# STM32H7B3ZIT6Q register map
File version: 1.0
Registers are 32-bit, access not given, reset 0x0 unless marked. A register's access mark holds for its fields unless they carry their own. Offsets are from the block's base; [hi:lo] are bit positions; {n}, {i} and the like mark numbered series.

## GFXMMU
Base 0x5200C000
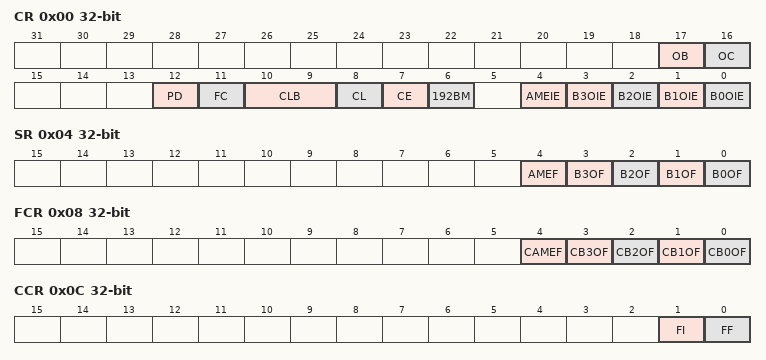
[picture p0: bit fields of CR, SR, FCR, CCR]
0x00 CR
  [17] OB, [16] OC, [12] PD, [11] FC, [10:9] CLB, [8] CL, [7] CE, [6] 192BM, [4] AMEIE, [n] B{n}OIE (n=0..3)
0x04 SR
  [4] AMEF, [n] B{n}OF (n=0..3)
0x08 FCR
  [4] CAMEF, [n] CB{n}OF (n=0..3)
0x0C CCR
  [1] FI, [0] FF
0x10 DVR
  [31:0] DV
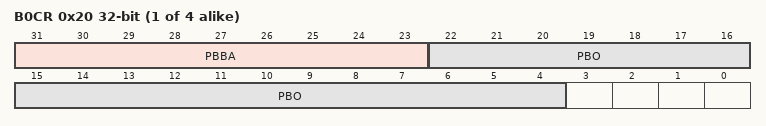
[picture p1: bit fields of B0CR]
{0x20+4i} B{i}CR (i=0..3)
  [31:23] PBBA, [22:4] PBO
0x1000 LUT.0
0x1004 LUT.1
0x1008 LUT.2
0x100C LUT.3
0x1010 LUT.4
0x1014 LUT.5
0x1018 LUT.6
0x101C LUT.7
0x1020 LUT.8
0x1024 LUT.9
0x1028 LUT.10
0x102C LUT.11
0x1030 LUT.12
0x1034 LUT.13
0x1038 LUT.14
0x103C LUT.15
0x1040 LUT.16
0x1044 LUT.17
0x1048 LUT.18
0x104C LUT.19
0x1050 LUT.20
0x1054 LUT.21
0x1058 LUT.22
0x105C LUT.23
0x1060 LUT.24
0x1064 LUT.25
0x1068 LUT.26
0x106C LUT.27
0x1070 LUT.28
0x1074 LUT.29
0x1078 LUT.30
0x107C LUT.31
0x1080 LUT.32
0x1084 LUT.33
0x1088 LUT.34
0x108C LUT.35
0x1090 LUT.36
0x1094 LUT.37
0x1098 LUT.38
0x109C LUT.39
0x10A0 LUT.40
0x10A4 LUT.41
0x10A8 LUT.42
0x10AC LUT.43
0x10B0 LUT.44
0x10B4 LUT.45
0x10B8 LUT.46
0x10BC LUT.47
0x10C0 LUT.48
0x10C4 LUT.49
0x10C8 LUT.50
0x10CC LUT.51
0x10D0 LUT.52
0x10D4 LUT.53
0x10D8 LUT.54
0x10DC LUT.55
0x10E0 LUT.56
0x10E4 LUT.57
0x10E8 LUT.58
0x10EC LUT.59
0x10F0 LUT.60
0x10F4 LUT.61
0x10F8 LUT.62
0x10FC LUT.63
0x1100 LUT.64
0x1104 LUT.65
0x1108 LUT.66
0x110C LUT.67
0x1110 LUT.68
0x1114 LUT.69
0x1118 LUT.70
0x111C LUT.71
0x1120 LUT.72
0x1124 LUT.73
0x1128 LUT.74
0x112C LUT.75
0x1130 LUT.76
0x1134 LUT.77
0x1138 LUT.78
0x113C LUT.79
0x1140 LUT.80
0x1144 LUT.81
0x1148 LUT.82
0x114C LUT.83
0x1150 LUT.84
0x1154 LUT.85
0x1158 LUT.86
0x115C LUT.87
0x1160 LUT.88
0x1164 LUT.89
0x1168 LUT.90
0x116C LUT.91
0x1170 LUT.92
0x1174 LUT.93
0x1178 LUT.94
0x117C LUT.95
0x1180 LUT.96
0x1184 LUT.97
0x1188 LUT.98
0x118C LUT.99
0x1190 LUT.100
0x1194 LUT.101
0x1198 LUT.102
0x119C LUT.103
0x11A0 LUT.104
0x11A4 LUT.105
0x11A8 LUT.106
0x11AC LUT.107
0x11B0 LUT.108
0x11B4 LUT.109
0x11B8 LUT.110
0x11BC LUT.111
0x11C0 LUT.112
0x11C4 LUT.113
0x11C8 LUT.114
0x11CC LUT.115
0x11D0 LUT.116
0x11D4 LUT.117
0x11D8 LUT.118
0x11DC LUT.119
0x11E0 LUT.120
0x11E4 LUT.121
0x11E8 LUT.122
0x11EC LUT.123
0x11F0 LUT.124
0x11F4 LUT.125
0x11F8 LUT.126
0x11FC LUT.127
0x1200 LUT.128
0x1204 LUT.129
0x1208 LUT.130
0x120C LUT.131
0x1210 LUT.132
0x1214 LUT.133
0x1218 LUT.134
0x121C LUT.135
0x1220 LUT.136
0x1224 LUT.137
0x1228 LUT.138
0x122C LUT.139
0x1230 LUT.140
0x1234 LUT.141
0x1238 LUT.142
0x123C LUT.143
0x1240 LUT.144
0x1244 LUT.145
0x1248 LUT.146
0x124C LUT.147
0x1250 LUT.148
0x1254 LUT.149
0x1258 LUT.150
0x125C LUT.151
0x1260 LUT.152
0x1264 LUT.153
0x1268 LUT.154
0x126C LUT.155
0x1270 LUT.156
0x1274 LUT.157
0x1278 LUT.158
0x127C LUT.159
0x1280 LUT.160
0x1284 LUT.161
0x1288 LUT.162
0x128C LUT.163
0x1290 LUT.164
0x1294 LUT.165
0x1298 LUT.166
0x129C LUT.167
0x12A0 LUT.168
0x12A4 LUT.169
0x12A8 LUT.170
0x12AC LUT.171
0x12B0 LUT.172
0x12B4 LUT.173
0x12B8 LUT.174
0x12BC LUT.175
0x12C0 LUT.176
0x12C4 LUT.177
0x12C8 LUT.178
0x12CC LUT.179
0x12D0 LUT.180
0x12D4 LUT.181
0x12D8 LUT.182
0x12DC LUT.183
0x12E0 LUT.184
0x12E4 LUT.185
0x12E8 LUT.186
0x12EC LUT.187
0x12F0 LUT.188
0x12F4 LUT.189
0x12F8 LUT.190
0x12FC LUT.191
0x1300 LUT.192
0x1304 LUT.193
0x1308 LUT.194
0x130C LUT.195
0x1310 LUT.196
0x1314 LUT.197
0x1318 LUT.198
0x131C LUT.199
0x1320 LUT.200
0x1324 LUT.201
0x1328 LUT.202
0x132C LUT.203
0x1330 LUT.204
0x1334 LUT.205
0x1338 LUT.206
0x133C LUT.207
0x1340 LUT.208
0x1344 LUT.209
0x1348 LUT.210
0x134C LUT.211
0x1350 LUT.212
0x1354 LUT.213
0x1358 LUT.214
0x135C LUT.215
0x1360 LUT.216
0x1364 LUT.217
0x1368 LUT.218
0x136C LUT.219
0x1370 LUT.220
0x1374 LUT.221
0x1378 LUT.222
0x137C LUT.223
0x1380 LUT.224
0x1384 LUT.225
0x1388 LUT.226
0x138C LUT.227
0x1390 LUT.228
0x1394 LUT.229
0x1398 LUT.230
0x139C LUT.231
0x13A0 LUT.232
0x13A4 LUT.233
0x13A8 LUT.234
0x13AC LUT.235
0x13B0 LUT.236
0x13B4 LUT.237
0x13B8 LUT.238
0x13BC LUT.239
0x13C0 LUT.240
0x13C4 LUT.241
0x13C8 LUT.242
0x13CC LUT.243
0x13D0 LUT.244
0x13D4 LUT.245
0x13D8 LUT.246
0x13DC LUT.247
0x13E0 LUT.248
0x13E4 LUT.249
0x13E8 LUT.250
0x13EC LUT.251
0x13F0 LUT.252
0x13F4 LUT.253
0x13F8 LUT.254
0x13FC LUT.255
0x1400 LUT.256
0x1404 LUT.257
0x1408 LUT.258
0x140C LUT.259
0x1410 LUT.260
0x1414 LUT.261
0x1418 LUT.262
0x141C LUT.263
0x1420 LUT.264
0x1424 LUT.265
0x1428 LUT.266
0x142C LUT.267
0x1430 LUT.268
0x1434 LUT.269
0x1438 LUT.270
0x143C LUT.271
0x1440 LUT.272
0x1444 LUT.273
0x1448 LUT.274
0x144C LUT.275
0x1450 LUT.276
0x1454 LUT.277
0x1458 LUT.278
0x145C LUT.279
0x1460 LUT.280
0x1464 LUT.281
0x1468 LUT.282
0x146C LUT.283
0x1470 LUT.284
0x1474 LUT.285
0x1478 LUT.286
0x147C LUT.287
0x1480 LUT.288
0x1484 LUT.289
0x1488 LUT.290
0x148C LUT.291
0x1490 LUT.292
0x1494 LUT.293
0x1498 LUT.294
0x149C LUT.295
0x14A0 LUT.296
0x14A4 LUT.297
0x14A8 LUT.298
0x14AC LUT.299
0x14B0 LUT.300
0x14B4 LUT.301
0x14B8 LUT.302
0x14BC LUT.303
0x14C0 LUT.304
0x14C4 LUT.305
0x14C8 LUT.306
0x14CC LUT.307
0x14D0 LUT.308
0x14D4 LUT.309
0x14D8 LUT.310
0x14DC LUT.311
0x14E0 LUT.312
0x14E4 LUT.313
0x14E8 LUT.314
0x14EC LUT.315
0x14F0 LUT.316
0x14F4 LUT.317
0x14F8 LUT.318
0x14FC LUT.319
0x1500 LUT.320
0x1504 LUT.321
0x1508 LUT.322
0x150C LUT.323
0x1510 LUT.324
0x1514 LUT.325
0x1518 LUT.326
0x151C LUT.327
0x1520 LUT.328
0x1524 LUT.329
0x1528 LUT.330
0x152C LUT.331
0x1530 LUT.332
0x1534 LUT.333
0x1538 LUT.334
0x153C LUT.335
0x1540 LUT.336
0x1544 LUT.337
0x1548 LUT.338
0x154C LUT.339
0x1550 LUT.340
0x1554 LUT.341
0x1558 LUT.342
0x155C LUT.343
0x1560 LUT.344
0x1564 LUT.345
0x1568 LUT.346
0x156C LUT.347
0x1570 LUT.348
0x1574 LUT.349
0x1578 LUT.350
0x157C LUT.351
0x1580 LUT.352
0x1584 LUT.353
0x1588 LUT.354
0x158C LUT.355
0x1590 LUT.356
0x1594 LUT.357
0x1598 LUT.358
0x159C LUT.359
0x15A0 LUT.360
0x15A4 LUT.361
0x15A8 LUT.362
0x15AC LUT.363
0x15B0 LUT.364
0x15B4 LUT.365
0x15B8 LUT.366
0x15BC LUT.367
0x15C0 LUT.368
0x15C4 LUT.369
0x15C8 LUT.370
0x15CC LUT.371
0x15D0 LUT.372
0x15D4 LUT.373
0x15D8 LUT.374
0x15DC LUT.375
0x15E0 LUT.376
0x15E4 LUT.377
0x15E8 LUT.378
0x15EC LUT.379
0x15F0 LUT.380
0x15F4 LUT.381
0x15F8 LUT.382
0x15FC LUT.383
0x1600 LUT.384
0x1604 LUT.385
0x1608 LUT.386
0x160C LUT.387
0x1610 LUT.388
0x1614 LUT.389
0x1618 LUT.390
0x161C LUT.391
0x1620 LUT.392
0x1624 LUT.393
0x1628 LUT.394
0x162C LUT.395
0x1630 LUT.396
0x1634 LUT.397
0x1638 LUT.398
0x163C LUT.399
0x1640 LUT.400
0x1644 LUT.401
0x1648 LUT.402
0x164C LUT.403
0x1650 LUT.404
0x1654 LUT.405
0x1658 LUT.406
0x165C LUT.407
0x1660 LUT.408
0x1664 LUT.409
0x1668 LUT.410
0x166C LUT.411
0x1670 LUT.412
0x1674 LUT.413
0x1678 LUT.414
0x167C LUT.415
0x1680 LUT.416
0x1684 LUT.417
0x1688 LUT.418
0x168C LUT.419
0x1690 LUT.420
0x1694 LUT.421
0x1698 LUT.422
0x169C LUT.423
0x16A0 LUT.424
0x16A4 LUT.425
0x16A8 LUT.426
0x16AC LUT.427
0x16B0 LUT.428
0x16B4 LUT.429
0x16B8 LUT.430
0x16BC LUT.431
0x16C0 LUT.432
0x16C4 LUT.433
0x16C8 LUT.434
0x16CC LUT.435
0x16D0 LUT.436
0x16D4 LUT.437
0x16D8 LUT.438
0x16DC LUT.439
0x16E0 LUT.440
0x16E4 LUT.441
0x16E8 LUT.442
0x16EC LUT.443
0x16F0 LUT.444
0x16F4 LUT.445
0x16F8 LUT.446
0x16FC LUT.447
0x1700 LUT.448
0x1704 LUT.449
0x1708 LUT.450
0x170C LUT.451
0x1710 LUT.452
0x1714 LUT.453
0x1718 LUT.454
0x171C LUT.455
0x1720 LUT.456
0x1724 LUT.457
0x1728 LUT.458
0x172C LUT.459
0x1730 LUT.460
0x1734 LUT.461
0x1738 LUT.462
0x173C LUT.463
0x1740 LUT.464
0x1744 LUT.465
0x1748 LUT.466
0x174C LUT.467
0x1750 LUT.468
0x1754 LUT.469
0x1758 LUT.470
0x175C LUT.471
0x1760 LUT.472
0x1764 LUT.473
0x1768 LUT.474
0x176C LUT.475
0x1770 LUT.476
0x1774 LUT.477
0x1778 LUT.478
0x177C LUT.479
0x1780 LUT.480
0x1784 LUT.481
0x1788 LUT.482
0x178C LUT.483
0x1790 LUT.484
0x1794 LUT.485
0x1798 LUT.486
0x179C LUT.487
0x17A0 LUT.488
0x17A4 LUT.489
0x17A8 LUT.490
0x17AC LUT.491
0x17B0 LUT.492
0x17B4 LUT.493
0x17B8 LUT.494
0x17BC LUT.495
0x17C0 LUT.496
0x17C4 LUT.497
0x17C8 LUT.498
0x17CC LUT.499
0x17D0 LUT.500
0x17D4 LUT.501
0x17D8 LUT.502
0x17DC LUT.503
0x17E0 LUT.504
0x17E4 LUT.505
0x17E8 LUT.506
0x17EC LUT.507
0x17F0 LUT.508
0x17F4 LUT.509
0x17F8 LUT.510
0x17FC LUT.511
0x1800 LUT.512
0x1804 LUT.513
0x1808 LUT.514
0x180C LUT.515
0x1810 LUT.516
0x1814 LUT.517
0x1818 LUT.518
0x181C LUT.519
0x1820 LUT.520
0x1824 LUT.521
0x1828 LUT.522
0x182C LUT.523
0x1830 LUT.524
0x1834 LUT.525
0x1838 LUT.526
0x183C LUT.527
0x1840 LUT.528
0x1844 LUT.529
0x1848 LUT.530
0x184C LUT.531
0x1850 LUT.532
0x1854 LUT.533
0x1858 LUT.534
0x185C LUT.535
0x1860 LUT.536
0x1864 LUT.537
0x1868 LUT.538
0x186C LUT.539
0x1870 LUT.540
0x1874 LUT.541
0x1878 LUT.542
0x187C LUT.543
0x1880 LUT.544
0x1884 LUT.545
0x1888 LUT.546
0x188C LUT.547
0x1890 LUT.548
0x1894 LUT.549
0x1898 LUT.550
0x189C LUT.551
0x18A0 LUT.552
0x18A4 LUT.553
0x18A8 LUT.554
0x18AC LUT.555
0x18B0 LUT.556
0x18B4 LUT.557
0x18B8 LUT.558
0x18BC LUT.559
0x18C0 LUT.560
0x18C4 LUT.561
0x18C8 LUT.562
0x18CC LUT.563
0x18D0 LUT.564
0x18D4 LUT.565
0x18D8 LUT.566
0x18DC LUT.567
0x18E0 LUT.568
0x18E4 LUT.569
0x18E8 LUT.570
0x18EC LUT.571
0x18F0 LUT.572
0x18F4 LUT.573
0x18F8 LUT.574
0x18FC LUT.575
0x1900 LUT.576
0x1904 LUT.577
0x1908 LUT.578
0x190C LUT.579
0x1910 LUT.580
0x1914 LUT.581
0x1918 LUT.582
0x191C LUT.583
0x1920 LUT.584
0x1924 LUT.585
0x1928 LUT.586
0x192C LUT.587
0x1930 LUT.588
0x1934 LUT.589
0x1938 LUT.590
0x193C LUT.591
0x1940 LUT.592
0x1944 LUT.593
0x1948 LUT.594
0x194C LUT.595
0x1950 LUT.596
0x1954 LUT.597
0x1958 LUT.598
0x195C LUT.599
0x1960 LUT.600
0x1964 LUT.601
0x1968 LUT.602
0x196C LUT.603
0x1970 LUT.604
0x1974 LUT.605
0x1978 LUT.606
0x197C LUT.607
0x1980 LUT.608
0x1984 LUT.609
0x1988 LUT.610
0x198C LUT.611
0x1990 LUT.612
0x1994 LUT.613
0x1998 LUT.614
0x199C LUT.615
0x19A0 LUT.616
0x19A4 LUT.617
0x19A8 LUT.618
0x19AC LUT.619
0x19B0 LUT.620
0x19B4 LUT.621
0x19B8 LUT.622
0x19BC LUT.623
0x19C0 LUT.624
0x19C4 LUT.625
0x19C8 LUT.626
0x19CC LUT.627
0x19D0 LUT.628
0x19D4 LUT.629
0x19D8 LUT.630
0x19DC LUT.631
0x19E0 LUT.632
0x19E4 LUT.633
0x19E8 LUT.634
0x19EC LUT.635
0x19F0 LUT.636
0x19F4 LUT.637
0x19F8 LUT.638
0x19FC LUT.639
0x1A00 LUT.640
0x1A04 LUT.641
0x1A08 LUT.642
0x1A0C LUT.643
0x1A10 LUT.644
0x1A14 LUT.645
0x1A18 LUT.646
0x1A1C LUT.647
0x1A20 LUT.648
0x1A24 LUT.649
0x1A28 LUT.650
0x1A2C LUT.651
0x1A30 LUT.652
0x1A34 LUT.653
0x1A38 LUT.654
0x1A3C LUT.655
0x1A40 LUT.656
0x1A44 LUT.657
0x1A48 LUT.658
0x1A4C LUT.659
0x1A50 LUT.660
0x1A54 LUT.661
0x1A58 LUT.662
0x1A5C LUT.663
0x1A60 LUT.664
0x1A64 LUT.665
0x1A68 LUT.666
0x1A6C LUT.667
0x1A70 LUT.668
0x1A74 LUT.669
0x1A78 LUT.670
0x1A7C LUT.671
0x1A80 LUT.672
0x1A84 LUT.673
0x1A88 LUT.674
0x1A8C LUT.675
0x1A90 LUT.676
0x1A94 LUT.677
0x1A98 LUT.678
0x1A9C LUT.679
0x1AA0 LUT.680
0x1AA4 LUT.681
0x1AA8 LUT.682
0x1AAC LUT.683
0x1AB0 LUT.684
0x1AB4 LUT.685
0x1AB8 LUT.686
0x1ABC LUT.687
0x1AC0 LUT.688
0x1AC4 LUT.689
0x1AC8 LUT.690
0x1ACC LUT.691
0x1AD0 LUT.692
0x1AD4 LUT.693
0x1AD8 LUT.694
0x1ADC LUT.695
0x1AE0 LUT.696
0x1AE4 LUT.697
0x1AE8 LUT.698
0x1AEC LUT.699
0x1AF0 LUT.700
0x1AF4 LUT.701
0x1AF8 LUT.702
0x1AFC LUT.703
0x1B00 LUT.704
0x1B04 LUT.705
0x1B08 LUT.706
0x1B0C LUT.707
0x1B10 LUT.708
0x1B14 LUT.709
0x1B18 LUT.710
0x1B1C LUT.711
0x1B20 LUT.712
0x1B24 LUT.713
0x1B28 LUT.714
0x1B2C LUT.715
0x1B30 LUT.716
0x1B34 LUT.717
0x1B38 LUT.718
0x1B3C LUT.719
0x1B40 LUT.720
0x1B44 LUT.721
0x1B48 LUT.722
0x1B4C LUT.723
0x1B50 LUT.724
0x1B54 LUT.725
0x1B58 LUT.726
0x1B5C LUT.727
0x1B60 LUT.728
0x1B64 LUT.729
0x1B68 LUT.730
0x1B6C LUT.731
0x1B70 LUT.732
0x1B74 LUT.733
0x1B78 LUT.734
0x1B7C LUT.735
0x1B80 LUT.736
0x1B84 LUT.737
0x1B88 LUT.738
0x1B8C LUT.739
0x1B90 LUT.740
0x1B94 LUT.741
0x1B98 LUT.742
0x1B9C LUT.743
0x1BA0 LUT.744
0x1BA4 LUT.745
0x1BA8 LUT.746
0x1BAC LUT.747
0x1BB0 LUT.748
0x1BB4 LUT.749
0x1BB8 LUT.750
0x1BBC LUT.751
0x1BC0 LUT.752
0x1BC4 LUT.753
0x1BC8 LUT.754
0x1BCC LUT.755
0x1BD0 LUT.756
0x1BD4 LUT.757
0x1BD8 LUT.758
0x1BDC LUT.759
0x1BE0 LUT.760
0x1BE4 LUT.761
0x1BE8 LUT.762
0x1BEC LUT.763
0x1BF0 LUT.764
0x1BF4 LUT.765
0x1BF8 LUT.766
0x1BFC LUT.767
0x1C00 LUT.768
0x1C04 LUT.769
0x1C08 LUT.770
0x1C0C LUT.771
0x1C10 LUT.772
0x1C14 LUT.773
0x1C18 LUT.774
0x1C1C LUT.775
0x1C20 LUT.776
0x1C24 LUT.777
0x1C28 LUT.778
0x1C2C LUT.779
0x1C30 LUT.780
0x1C34 LUT.781
0x1C38 LUT.782
0x1C3C LUT.783
0x1C40 LUT.784
0x1C44 LUT.785
0x1C48 LUT.786
0x1C4C LUT.787
0x1C50 LUT.788
0x1C54 LUT.789
0x1C58 LUT.790
0x1C5C LUT.791
0x1C60 LUT.792
0x1C64 LUT.793
0x1C68 LUT.794
0x1C6C LUT.795
0x1C70 LUT.796
0x1C74 LUT.797
0x1C78 LUT.798
0x1C7C LUT.799
0x1C80 LUT.800
0x1C84 LUT.801
0x1C88 LUT.802
0x1C8C LUT.803
0x1C90 LUT.804
0x1C94 LUT.805
0x1C98 LUT.806
0x1C9C LUT.807
0x1CA0 LUT.808
0x1CA4 LUT.809
0x1CA8 LUT.810
0x1CAC LUT.811
0x1CB0 LUT.812
0x1CB4 LUT.813
0x1CB8 LUT.814
0x1CBC LUT.815
0x1CC0 LUT.816
0x1CC4 LUT.817
0x1CC8 LUT.818
0x1CCC LUT.819
0x1CD0 LUT.820
0x1CD4 LUT.821
0x1CD8 LUT.822
0x1CDC LUT.823
0x1CE0 LUT.824
0x1CE4 LUT.825
0x1CE8 LUT.826
0x1CEC LUT.827
0x1CF0 LUT.828
0x1CF4 LUT.829
0x1CF8 LUT.830
0x1CFC LUT.831
0x1D00 LUT.832
0x1D04 LUT.833
0x1D08 LUT.834
0x1D0C LUT.835
0x1D10 LUT.836
0x1D14 LUT.837
0x1D18 LUT.838
0x1D1C LUT.839
0x1D20 LUT.840
0x1D24 LUT.841
0x1D28 LUT.842
0x1D2C LUT.843
0x1D30 LUT.844
0x1D34 LUT.845
0x1D38 LUT.846
0x1D3C LUT.847
0x1D40 LUT.848
0x1D44 LUT.849
0x1D48 LUT.850
0x1D4C LUT.851
0x1D50 LUT.852
0x1D54 LUT.853
0x1D58 LUT.854
0x1D5C LUT.855
0x1D60 LUT.856
0x1D64 LUT.857
0x1D68 LUT.858
0x1D6C LUT.859
0x1D70 LUT.860
0x1D74 LUT.861
0x1D78 LUT.862
0x1D7C LUT.863
0x1D80 LUT.864
0x1D84 LUT.865
0x1D88 LUT.866
0x1D8C LUT.867
0x1D90 LUT.868
0x1D94 LUT.869
0x1D98 LUT.870
0x1D9C LUT.871
0x1DA0 LUT.872
0x1DA4 LUT.873
0x1DA8 LUT.874
0x1DAC LUT.875
0x1DB0 LUT.876
0x1DB4 LUT.877
0x1DB8 LUT.878
0x1DBC LUT.879
0x1DC0 LUT.880
0x1DC4 LUT.881
0x1DC8 LUT.882
0x1DCC LUT.883
0x1DD0 LUT.884
0x1DD4 LUT.885
0x1DD8 LUT.886
0x1DDC LUT.887
0x1DE0 LUT.888
0x1DE4 LUT.889
0x1DE8 LUT.890
0x1DEC LUT.891
0x1DF0 LUT.892
0x1DF4 LUT.893
0x1DF8 LUT.894
0x1DFC LUT.895
0x1E00 LUT.896
0x1E04 LUT.897
0x1E08 LUT.898
0x1E0C LUT.899
0x1E10 LUT.900
0x1E14 LUT.901
0x1E18 LUT.902
0x1E1C LUT.903
0x1E20 LUT.904
0x1E24 LUT.905
0x1E28 LUT.906
0x1E2C LUT.907
0x1E30 LUT.908
0x1E34 LUT.909
0x1E38 LUT.910
0x1E3C LUT.911
0x1E40 LUT.912
0x1E44 LUT.913
0x1E48 LUT.914
0x1E4C LUT.915
0x1E50 LUT.916
0x1E54 LUT.917
0x1E58 LUT.918
0x1E5C LUT.919
0x1E60 LUT.920
0x1E64 LUT.921
0x1E68 LUT.922
0x1E6C LUT.923
0x1E70 LUT.924
0x1E74 LUT.925
0x1E78 LUT.926
0x1E7C LUT.927
0x1E80 LUT.928
0x1E84 LUT.929
0x1E88 LUT.930
0x1E8C LUT.931
0x1E90 LUT.932
0x1E94 LUT.933
0x1E98 LUT.934
0x1E9C LUT.935
0x1EA0 LUT.936
0x1EA4 LUT.937
0x1EA8 LUT.938
0x1EAC LUT.939
0x1EB0 LUT.940
0x1EB4 LUT.941
0x1EB8 LUT.942
0x1EBC LUT.943
0x1EC0 LUT.944
0x1EC4 LUT.945
0x1EC8 LUT.946
0x1ECC LUT.947
0x1ED0 LUT.948
0x1ED4 LUT.949
0x1ED8 LUT.950
0x1EDC LUT.951
0x1EE0 LUT.952
0x1EE4 LUT.953
0x1EE8 LUT.954
0x1EEC LUT.955
0x1EF0 LUT.956
0x1EF4 LUT.957
0x1EF8 LUT.958
0x1EFC LUT.959
0x1F00 LUT.960
0x1F04 LUT.961
0x1F08 LUT.962
0x1F0C LUT.963
0x1F10 LUT.964
0x1F14 LUT.965
0x1F18 LUT.966
0x1F1C LUT.967
0x1F20 LUT.968
0x1F24 LUT.969
0x1F28 LUT.970
0x1F2C LUT.971
0x1F30 LUT.972
0x1F34 LUT.973
0x1F38 LUT.974
0x1F3C LUT.975
0x1F40 LUT.976
0x1F44 LUT.977
0x1F48 LUT.978
0x1F4C LUT.979
0x1F50 LUT.980
0x1F54 LUT.981
0x1F58 LUT.982
0x1F5C LUT.983
0x1F60 LUT.984
0x1F64 LUT.985
0x1F68 LUT.986
0x1F6C LUT.987
0x1F70 LUT.988
0x1F74 LUT.989
0x1F78 LUT.990
0x1F7C LUT.991
0x1F80 LUT.992
0x1F84 LUT.993
0x1F88 LUT.994
0x1F8C LUT.995
0x1F90 LUT.996
0x1F94 LUT.997
0x1F98 LUT.998
0x1F9C LUT.999
0x1FA0 LUT.1000
0x1FA4 LUT.1001
0x1FA8 LUT.1002
0x1FAC LUT.1003
0x1FB0 LUT.1004
0x1FB4 LUT.1005
0x1FB8 LUT.1006
0x1FBC LUT.1007
0x1FC0 LUT.1008
0x1FC4 LUT.1009
0x1FC8 LUT.1010
0x1FCC LUT.1011
0x1FD0 LUT.1012
0x1FD4 LUT.1013
0x1FD8 LUT.1014
0x1FDC LUT.1015
0x1FE0 LUT.1016
0x1FE4 LUT.1017
0x1FE8 LUT.1018
0x1FEC LUT.1019
0x1FF0 LUT.1020
0x1FF4 LUT.1021
0x1FF8 LUT.1022
0x1FFC LUT.1023
0x2000 LUT.1024
0x2004 LUT.1025
0x2008 LUT.1026
0x200C LUT.1027
0x2010 LUT.1028
0x2014 LUT.1029
0x2018 LUT.1030
0x201C LUT.1031
0x2020 LUT.1032
0x2024 LUT.1033
0x2028 LUT.1034
0x202C LUT.1035
0x2030 LUT.1036
0x2034 LUT.1037
0x2038 LUT.1038
0x203C LUT.1039
0x2040 LUT.1040
0x2044 LUT.1041
0x2048 LUT.1042
0x204C LUT.1043
0x2050 LUT.1044
0x2054 LUT.1045
0x2058 LUT.1046
0x205C LUT.1047
0x2060 LUT.1048
0x2064 LUT.1049
0x2068 LUT.1050
0x206C LUT.1051
0x2070 LUT.1052
0x2074 LUT.1053
0x2078 LUT.1054
0x207C LUT.1055
0x2080 LUT.1056
0x2084 LUT.1057
0x2088 LUT.1058
0x208C LUT.1059
0x2090 LUT.1060
0x2094 LUT.1061
0x2098 LUT.1062
0x209C LUT.1063
0x20A0 LUT.1064
0x20A4 LUT.1065
0x20A8 LUT.1066
0x20AC LUT.1067
0x20B0 LUT.1068
0x20B4 LUT.1069
0x20B8 LUT.1070
0x20BC LUT.1071
0x20C0 LUT.1072
0x20C4 LUT.1073
0x20C8 LUT.1074
0x20CC LUT.1075
0x20D0 LUT.1076
0x20D4 LUT.1077
0x20D8 LUT.1078
0x20DC LUT.1079
0x20E0 LUT.1080
0x20E4 LUT.1081
0x20E8 LUT.1082
0x20EC LUT.1083
0x20F0 LUT.1084
0x20F4 LUT.1085
0x20F8 LUT.1086
0x20FC LUT.1087
0x2100 LUT.1088
0x2104 LUT.1089
0x2108 LUT.1090
0x210C LUT.1091
0x2110 LUT.1092
0x2114 LUT.1093
0x2118 LUT.1094
0x211C LUT.1095
0x2120 LUT.1096
0x2124 LUT.1097
0x2128 LUT.1098
0x212C LUT.1099
0x2130 LUT.1100
0x2134 LUT.1101
0x2138 LUT.1102
0x213C LUT.1103
0x2140 LUT.1104
0x2144 LUT.1105
0x2148 LUT.1106
0x214C LUT.1107
0x2150 LUT.1108
0x2154 LUT.1109
0x2158 LUT.1110
0x215C LUT.1111
0x2160 LUT.1112
0x2164 LUT.1113
0x2168 LUT.1114
0x216C LUT.1115
0x2170 LUT.1116
0x2174 LUT.1117
0x2178 LUT.1118
0x217C LUT.1119
0x2180 LUT.1120
0x2184 LUT.1121
0x2188 LUT.1122
0x218C LUT.1123
0x2190 LUT.1124
0x2194 LUT.1125
0x2198 LUT.1126
0x219C LUT.1127
0x21A0 LUT.1128
0x21A4 LUT.1129
0x21A8 LUT.1130
0x21AC LUT.1131
0x21B0 LUT.1132
0x21B4 LUT.1133
0x21B8 LUT.1134
0x21BC LUT.1135
0x21C0 LUT.1136
0x21C4 LUT.1137
0x21C8 LUT.1138
0x21CC LUT.1139
0x21D0 LUT.1140
0x21D4 LUT.1141
0x21D8 LUT.1142
0x21DC LUT.1143
0x21E0 LUT.1144
0x21E4 LUT.1145
0x21E8 LUT.1146
0x21EC LUT.1147
0x21F0 LUT.1148
0x21F4 LUT.1149
0x21F8 LUT.1150
0x21FC LUT.1151
0x2200 LUT.1152
0x2204 LUT.1153
0x2208 LUT.1154
0x220C LUT.1155
0x2210 LUT.1156
0x2214 LUT.1157
0x2218 LUT.1158
0x221C LUT.1159
0x2220 LUT.1160
0x2224 LUT.1161
0x2228 LUT.1162
0x222C LUT.1163
0x2230 LUT.1164
0x2234 LUT.1165
0x2238 LUT.1166
0x223C LUT.1167
0x2240 LUT.1168
0x2244 LUT.1169
0x2248 LUT.1170
0x224C LUT.1171
0x2250 LUT.1172
0x2254 LUT.1173
0x2258 LUT.1174
0x225C LUT.1175
0x2260 LUT.1176
0x2264 LUT.1177
0x2268 LUT.1178
0x226C LUT.1179
0x2270 LUT.1180
0x2274 LUT.1181
0x2278 LUT.1182
0x227C LUT.1183
0x2280 LUT.1184
0x2284 LUT.1185
0x2288 LUT.1186
0x228C LUT.1187
0x2290 LUT.1188
0x2294 LUT.1189
0x2298 LUT.1190
0x229C LUT.1191
0x22A0 LUT.1192
0x22A4 LUT.1193
0x22A8 LUT.1194
0x22AC LUT.1195
0x22B0 LUT.1196
0x22B4 LUT.1197
0x22B8 LUT.1198
0x22BC LUT.1199
0x22C0 LUT.1200
0x22C4 LUT.1201
0x22C8 LUT.1202
0x22CC LUT.1203
0x22D0 LUT.1204
0x22D4 LUT.1205
0x22D8 LUT.1206
0x22DC LUT.1207
0x22E0 LUT.1208
0x22E4 LUT.1209
0x22E8 LUT.1210
0x22EC LUT.1211
0x22F0 LUT.1212
0x22F4 LUT.1213
0x22F8 LUT.1214
0x22FC LUT.1215
0x2300 LUT.1216
0x2304 LUT.1217
0x2308 LUT.1218
0x230C LUT.1219
0x2310 LUT.1220
0x2314 LUT.1221
0x2318 LUT.1222
0x231C LUT.1223
0x2320 LUT.1224
0x2324 LUT.1225
0x2328 LUT.1226
0x232C LUT.1227
0x2330 LUT.1228
0x2334 LUT.1229
0x2338 LUT.1230
0x233C LUT.1231
0x2340 LUT.1232
0x2344 LUT.1233
0x2348 LUT.1234
0x234C LUT.1235
0x2350 LUT.1236
0x2354 LUT.1237
0x2358 LUT.1238
0x235C LUT.1239
0x2360 LUT.1240
0x2364 LUT.1241
0x2368 LUT.1242
0x236C LUT.1243
0x2370 LUT.1244
0x2374 LUT.1245
0x2378 LUT.1246
0x237C LUT.1247
0x2380 LUT.1248
0x2384 LUT.1249
0x2388 LUT.1250
0x238C LUT.1251
0x2390 LUT.1252
0x2394 LUT.1253
0x2398 LUT.1254
0x239C LUT.1255
0x23A0 LUT.1256
0x23A4 LUT.1257
0x23A8 LUT.1258
0x23AC LUT.1259
0x23B0 LUT.1260
0x23B4 LUT.1261
0x23B8 LUT.1262
0x23BC LUT.1263
0x23C0 LUT.1264
0x23C4 LUT.1265
0x23C8 LUT.1266
0x23CC LUT.1267
0x23D0 LUT.1268
0x23D4 LUT.1269
0x23D8 LUT.1270
0x23DC LUT.1271
0x23E0 LUT.1272
0x23E4 LUT.1273
0x23E8 LUT.1274
0x23EC LUT.1275
0x23F0 LUT.1276
0x23F4 LUT.1277
0x23F8 LUT.1278
0x23FC LUT.1279
0x2400 LUT.1280
0x2404 LUT.1281
0x2408 LUT.1282
0x240C LUT.1283
0x2410 LUT.1284
0x2414 LUT.1285
0x2418 LUT.1286
0x241C LUT.1287
0x2420 LUT.1288
0x2424 LUT.1289
0x2428 LUT.1290
0x242C LUT.1291
0x2430 LUT.1292
0x2434 LUT.1293
0x2438 LUT.1294
0x243C LUT.1295
0x2440 LUT.1296
0x2444 LUT.1297
0x2448 LUT.1298
0x244C LUT.1299
0x2450 LUT.1300
0x2454 LUT.1301
0x2458 LUT.1302
0x245C LUT.1303
0x2460 LUT.1304
0x2464 LUT.1305
0x2468 LUT.1306
0x246C LUT.1307
0x2470 LUT.1308
0x2474 LUT.1309
0x2478 LUT.1310
0x247C LUT.1311
0x2480 LUT.1312
0x2484 LUT.1313
0x2488 LUT.1314
0x248C LUT.1315
0x2490 LUT.1316
0x2494 LUT.1317
0x2498 LUT.1318
0x249C LUT.1319
0x24A0 LUT.1320
0x24A4 LUT.1321
0x24A8 LUT.1322
0x24AC LUT.1323
0x24B0 LUT.1324
0x24B4 LUT.1325
0x24B8 LUT.1326
0x24BC LUT.1327
0x24C0 LUT.1328
0x24C4 LUT.1329
0x24C8 LUT.1330
0x24CC LUT.1331
0x24D0 LUT.1332
0x24D4 LUT.1333
0x24D8 LUT.1334
0x24DC LUT.1335
0x24E0 LUT.1336
0x24E4 LUT.1337
0x24E8 LUT.1338
0x24EC LUT.1339
0x24F0 LUT.1340
0x24F4 LUT.1341
0x24F8 LUT.1342
0x24FC LUT.1343
0x2500 LUT.1344
0x2504 LUT.1345
0x2508 LUT.1346
0x250C LUT.1347
0x2510 LUT.1348
0x2514 LUT.1349
0x2518 LUT.1350
0x251C LUT.1351
0x2520 LUT.1352
0x2524 LUT.1353
0x2528 LUT.1354
0x252C LUT.1355
0x2530 LUT.1356
0x2534 LUT.1357
0x2538 LUT.1358
0x253C LUT.1359
0x2540 LUT.1360
0x2544 LUT.1361
0x2548 LUT.1362
0x254C LUT.1363
0x2550 LUT.1364
0x2554 LUT.1365
0x2558 LUT.1366
0x255C LUT.1367
0x2560 LUT.1368
0x2564 LUT.1369
0x2568 LUT.1370
0x256C LUT.1371
0x2570 LUT.1372
0x2574 LUT.1373
0x2578 LUT.1374
0x257C LUT.1375
0x2580 LUT.1376
0x2584 LUT.1377
0x2588 LUT.1378
0x258C LUT.1379
0x2590 LUT.1380
0x2594 LUT.1381
0x2598 LUT.1382
0x259C LUT.1383
0x25A0 LUT.1384
0x25A4 LUT.1385
0x25A8 LUT.1386
0x25AC LUT.1387
0x25B0 LUT.1388
0x25B4 LUT.1389
0x25B8 LUT.1390
0x25BC LUT.1391
0x25C0 LUT.1392
0x25C4 LUT.1393
0x25C8 LUT.1394
0x25CC LUT.1395
0x25D0 LUT.1396
0x25D4 LUT.1397
0x25D8 LUT.1398
0x25DC LUT.1399
0x25E0 LUT.1400
0x25E4 LUT.1401
0x25E8 LUT.1402
0x25EC LUT.1403
0x25F0 LUT.1404
0x25F4 LUT.1405
0x25F8 LUT.1406
0x25FC LUT.1407
0x2600 LUT.1408
0x2604 LUT.1409
0x2608 LUT.1410
0x260C LUT.1411
0x2610 LUT.1412
0x2614 LUT.1413
0x2618 LUT.1414
0x261C LUT.1415
0x2620 LUT.1416
0x2624 LUT.1417
0x2628 LUT.1418
0x262C LUT.1419
0x2630 LUT.1420
0x2634 LUT.1421
0x2638 LUT.1422
0x263C LUT.1423
0x2640 LUT.1424
0x2644 LUT.1425
0x2648 LUT.1426
0x264C LUT.1427
0x2650 LUT.1428
0x2654 LUT.1429
0x2658 LUT.1430
0x265C LUT.1431
0x2660 LUT.1432
0x2664 LUT.1433
0x2668 LUT.1434
0x266C LUT.1435
0x2670 LUT.1436
0x2674 LUT.1437
0x2678 LUT.1438
0x267C LUT.1439
0x2680 LUT.1440
0x2684 LUT.1441
0x2688 LUT.1442
0x268C LUT.1443
0x2690 LUT.1444
0x2694 LUT.1445
0x2698 LUT.1446
0x269C LUT.1447
0x26A0 LUT.1448
0x26A4 LUT.1449
0x26A8 LUT.1450
0x26AC LUT.1451
0x26B0 LUT.1452
0x26B4 LUT.1453
0x26B8 LUT.1454
0x26BC LUT.1455
0x26C0 LUT.1456
0x26C4 LUT.1457
0x26C8 LUT.1458
0x26CC LUT.1459
0x26D0 LUT.1460
0x26D4 LUT.1461
0x26D8 LUT.1462
0x26DC LUT.1463
0x26E0 LUT.1464
0x26E4 LUT.1465
0x26E8 LUT.1466
0x26EC LUT.1467
0x26F0 LUT.1468
0x26F4 LUT.1469
0x26F8 LUT.1470
0x26FC LUT.1471
0x2700 LUT.1472
0x2704 LUT.1473
0x2708 LUT.1474
0x270C LUT.1475
0x2710 LUT.1476
0x2714 LUT.1477
0x2718 LUT.1478
0x271C LUT.1479
0x2720 LUT.1480
0x2724 LUT.1481
0x2728 LUT.1482
0x272C LUT.1483
0x2730 LUT.1484
0x2734 LUT.1485
0x2738 LUT.1486
0x273C LUT.1487
0x2740 LUT.1488
0x2744 LUT.1489
0x2748 LUT.1490
0x274C LUT.1491
0x2750 LUT.1492
0x2754 LUT.1493
0x2758 LUT.1494
0x275C LUT.1495
0x2760 LUT.1496
0x2764 LUT.1497
0x2768 LUT.1498
0x276C LUT.1499
0x2770 LUT.1500
0x2774 LUT.1501
0x2778 LUT.1502
0x277C LUT.1503
0x2780 LUT.1504
0x2784 LUT.1505
0x2788 LUT.1506
0x278C LUT.1507
0x2790 LUT.1508
0x2794 LUT.1509
0x2798 LUT.1510
0x279C LUT.1511
0x27A0 LUT.1512
0x27A4 LUT.1513
0x27A8 LUT.1514
0x27AC LUT.1515
0x27B0 LUT.1516
0x27B4 LUT.1517
0x27B8 LUT.1518
0x27BC LUT.1519
0x27C0 LUT.1520
0x27C4 LUT.1521
0x27C8 LUT.1522
0x27CC LUT.1523
0x27D0 LUT.1524
0x27D4 LUT.1525
0x27D8 LUT.1526
0x27DC LUT.1527
0x27E0 LUT.1528
0x27E4 LUT.1529
0x27E8 LUT.1530
0x27EC LUT.1531
0x27F0 LUT.1532
0x27F4 LUT.1533
0x27F8 LUT.1534
0x27FC LUT.1535
0x2800 LUT.1536
0x2804 LUT.1537
0x2808 LUT.1538
0x280C LUT.1539
0x2810 LUT.1540
0x2814 LUT.1541
0x2818 LUT.1542
0x281C LUT.1543
0x2820 LUT.1544
0x2824 LUT.1545
0x2828 LUT.1546
0x282C LUT.1547
0x2830 LUT.1548
0x2834 LUT.1549
0x2838 LUT.1550
0x283C LUT.1551
0x2840 LUT.1552
0x2844 LUT.1553
0x2848 LUT.1554
0x284C LUT.1555
0x2850 LUT.1556
0x2854 LUT.1557
0x2858 LUT.1558
0x285C LUT.1559
0x2860 LUT.1560
0x2864 LUT.1561
0x2868 LUT.1562
0x286C LUT.1563
0x2870 LUT.1564
0x2874 LUT.1565
0x2878 LUT.1566
0x287C LUT.1567
0x2880 LUT.1568
0x2884 LUT.1569
0x2888 LUT.1570
0x288C LUT.1571
0x2890 LUT.1572
0x2894 LUT.1573
0x2898 LUT.1574
0x289C LUT.1575
0x28A0 LUT.1576
0x28A4 LUT.1577
0x28A8 LUT.1578
0x28AC LUT.1579
0x28B0 LUT.1580
0x28B4 LUT.1581
0x28B8 LUT.1582
0x28BC LUT.1583
0x28C0 LUT.1584
0x28C4 LUT.1585
0x28C8 LUT.1586
0x28CC LUT.1587
0x28D0 LUT.1588
0x28D4 LUT.1589
0x28D8 LUT.1590
0x28DC LUT.1591
0x28E0 LUT.1592
0x28E4 LUT.1593
0x28E8 LUT.1594
0x28EC LUT.1595
0x28F0 LUT.1596
0x28F4 LUT.1597
0x28F8 LUT.1598
0x28FC LUT.1599
0x2900 LUT.1600
0x2904 LUT.1601
0x2908 LUT.1602
0x290C LUT.1603
0x2910 LUT.1604
0x2914 LUT.1605
0x2918 LUT.1606
0x291C LUT.1607
0x2920 LUT.1608
0x2924 LUT.1609
0x2928 LUT.1610
0x292C LUT.1611
0x2930 LUT.1612
0x2934 LUT.1613
0x2938 LUT.1614
0x293C LUT.1615
0x2940 LUT.1616
0x2944 LUT.1617
0x2948 LUT.1618
0x294C LUT.1619
0x2950 LUT.1620
0x2954 LUT.1621
0x2958 LUT.1622
0x295C LUT.1623
0x2960 LUT.1624
0x2964 LUT.1625
0x2968 LUT.1626
0x296C LUT.1627
0x2970 LUT.1628
0x2974 LUT.1629
0x2978 LUT.1630
0x297C LUT.1631
0x2980 LUT.1632
0x2984 LUT.1633
0x2988 LUT.1634
0x298C LUT.1635
0x2990 LUT.1636
0x2994 LUT.1637
0x2998 LUT.1638
0x299C LUT.1639
0x29A0 LUT.1640
0x29A4 LUT.1641
0x29A8 LUT.1642
0x29AC LUT.1643
0x29B0 LUT.1644
0x29B4 LUT.1645
0x29B8 LUT.1646
0x29BC LUT.1647
0x29C0 LUT.1648
0x29C4 LUT.1649
0x29C8 LUT.1650
0x29CC LUT.1651
0x29D0 LUT.1652
0x29D4 LUT.1653
0x29D8 LUT.1654
0x29DC LUT.1655
0x29E0 LUT.1656
0x29E4 LUT.1657
0x29E8 LUT.1658
0x29EC LUT.1659
0x29F0 LUT.1660
0x29F4 LUT.1661
0x29F8 LUT.1662
0x29FC LUT.1663
0x2A00 LUT.1664
0x2A04 LUT.1665
0x2A08 LUT.1666
0x2A0C LUT.1667
0x2A10 LUT.1668
0x2A14 LUT.1669
0x2A18 LUT.1670
0x2A1C LUT.1671
0x2A20 LUT.1672
0x2A24 LUT.1673
0x2A28 LUT.1674
0x2A2C LUT.1675
0x2A30 LUT.1676
0x2A34 LUT.1677
0x2A38 LUT.1678
0x2A3C LUT.1679
0x2A40 LUT.1680
0x2A44 LUT.1681
0x2A48 LUT.1682
0x2A4C LUT.1683
0x2A50 LUT.1684
0x2A54 LUT.1685
0x2A58 LUT.1686
0x2A5C LUT.1687
0x2A60 LUT.1688
0x2A64 LUT.1689
0x2A68 LUT.1690
0x2A6C LUT.1691
0x2A70 LUT.1692
0x2A74 LUT.1693
0x2A78 LUT.1694
0x2A7C LUT.1695
0x2A80 LUT.1696
0x2A84 LUT.1697
0x2A88 LUT.1698
0x2A8C LUT.1699
0x2A90 LUT.1700
0x2A94 LUT.1701
0x2A98 LUT.1702
0x2A9C LUT.1703
0x2AA0 LUT.1704
0x2AA4 LUT.1705
0x2AA8 LUT.1706
0x2AAC LUT.1707
0x2AB0 LUT.1708
0x2AB4 LUT.1709
0x2AB8 LUT.1710
0x2ABC LUT.1711
0x2AC0 LUT.1712
0x2AC4 LUT.1713
0x2AC8 LUT.1714
0x2ACC LUT.1715
0x2AD0 LUT.1716
0x2AD4 LUT.1717
0x2AD8 LUT.1718
0x2ADC LUT.1719
0x2AE0 LUT.1720
0x2AE4 LUT.1721
0x2AE8 LUT.1722
0x2AEC LUT.1723
0x2AF0 LUT.1724
0x2AF4 LUT.1725
0x2AF8 LUT.1726
0x2AFC LUT.1727
0x2B00 LUT.1728
0x2B04 LUT.1729
0x2B08 LUT.1730
0x2B0C LUT.1731
0x2B10 LUT.1732
0x2B14 LUT.1733
0x2B18 LUT.1734
0x2B1C LUT.1735
0x2B20 LUT.1736
0x2B24 LUT.1737
0x2B28 LUT.1738
0x2B2C LUT.1739
0x2B30 LUT.1740
0x2B34 LUT.1741
0x2B38 LUT.1742
0x2B3C LUT.1743
0x2B40 LUT.1744
0x2B44 LUT.1745
0x2B48 LUT.1746
0x2B4C LUT.1747
0x2B50 LUT.1748
0x2B54 LUT.1749
0x2B58 LUT.1750
0x2B5C LUT.1751
0x2B60 LUT.1752
0x2B64 LUT.1753
0x2B68 LUT.1754
0x2B6C LUT.1755
0x2B70 LUT.1756
0x2B74 LUT.1757
0x2B78 LUT.1758
0x2B7C LUT.1759
0x2B80 LUT.1760
0x2B84 LUT.1761
0x2B88 LUT.1762
0x2B8C LUT.1763
0x2B90 LUT.1764
0x2B94 LUT.1765
0x2B98 LUT.1766
0x2B9C LUT.1767
0x2BA0 LUT.1768
0x2BA4 LUT.1769
0x2BA8 LUT.1770
0x2BAC LUT.1771
0x2BB0 LUT.1772
0x2BB4 LUT.1773
0x2BB8 LUT.1774
0x2BBC LUT.1775
0x2BC0 LUT.1776
0x2BC4 LUT.1777
0x2BC8 LUT.1778
0x2BCC LUT.1779
0x2BD0 LUT.1780
0x2BD4 LUT.1781
0x2BD8 LUT.1782
0x2BDC LUT.1783
0x2BE0 LUT.1784
0x2BE4 LUT.1785
0x2BE8 LUT.1786
0x2BEC LUT.1787
0x2BF0 LUT.1788
0x2BF4 LUT.1789
0x2BF8 LUT.1790
0x2BFC LUT.1791
0x2C00 LUT.1792
0x2C04 LUT.1793
0x2C08 LUT.1794
0x2C0C LUT.1795
0x2C10 LUT.1796
0x2C14 LUT.1797
0x2C18 LUT.1798
0x2C1C LUT.1799
0x2C20 LUT.1800
0x2C24 LUT.1801
0x2C28 LUT.1802
0x2C2C LUT.1803
0x2C30 LUT.1804
0x2C34 LUT.1805
0x2C38 LUT.1806
0x2C3C LUT.1807
0x2C40 LUT.1808
0x2C44 LUT.1809
0x2C48 LUT.1810
0x2C4C LUT.1811
0x2C50 LUT.1812
0x2C54 LUT.1813
0x2C58 LUT.1814
0x2C5C LUT.1815
0x2C60 LUT.1816
0x2C64 LUT.1817
0x2C68 LUT.1818
0x2C6C LUT.1819
0x2C70 LUT.1820
0x2C74 LUT.1821
0x2C78 LUT.1822
0x2C7C LUT.1823
0x2C80 LUT.1824
0x2C84 LUT.1825
0x2C88 LUT.1826
0x2C8C LUT.1827
0x2C90 LUT.1828
0x2C94 LUT.1829
0x2C98 LUT.1830
0x2C9C LUT.1831
0x2CA0 LUT.1832
0x2CA4 LUT.1833
0x2CA8 LUT.1834
0x2CAC LUT.1835
0x2CB0 LUT.1836
0x2CB4 LUT.1837
0x2CB8 LUT.1838
0x2CBC LUT.1839
0x2CC0 LUT.1840
0x2CC4 LUT.1841
0x2CC8 LUT.1842
0x2CCC LUT.1843
0x2CD0 LUT.1844
0x2CD4 LUT.1845
0x2CD8 LUT.1846
0x2CDC LUT.1847
0x2CE0 LUT.1848
0x2CE4 LUT.1849
0x2CE8 LUT.1850
0x2CEC LUT.1851
0x2CF0 LUT.1852
0x2CF4 LUT.1853
0x2CF8 LUT.1854
0x2CFC LUT.1855
0x2D00 LUT.1856
0x2D04 LUT.1857
0x2D08 LUT.1858
0x2D0C LUT.1859
0x2D10 LUT.1860
0x2D14 LUT.1861
0x2D18 LUT.1862
0x2D1C LUT.1863
0x2D20 LUT.1864
0x2D24 LUT.1865
0x2D28 LUT.1866
0x2D2C LUT.1867
0x2D30 LUT.1868
0x2D34 LUT.1869
0x2D38 LUT.1870
0x2D3C LUT.1871
0x2D40 LUT.1872
0x2D44 LUT.1873
0x2D48 LUT.1874
0x2D4C LUT.1875
0x2D50 LUT.1876
0x2D54 LUT.1877
0x2D58 LUT.1878
0x2D5C LUT.1879
0x2D60 LUT.1880
0x2D64 LUT.1881
0x2D68 LUT.1882
0x2D6C LUT.1883
0x2D70 LUT.1884
0x2D74 LUT.1885
0x2D78 LUT.1886
0x2D7C LUT.1887
0x2D80 LUT.1888
0x2D84 LUT.1889
0x2D88 LUT.1890
0x2D8C LUT.1891
0x2D90 LUT.1892
0x2D94 LUT.1893
0x2D98 LUT.1894
0x2D9C LUT.1895
0x2DA0 LUT.1896
0x2DA4 LUT.1897
0x2DA8 LUT.1898
0x2DAC LUT.1899
0x2DB0 LUT.1900
0x2DB4 LUT.1901
0x2DB8 LUT.1902
0x2DBC LUT.1903
0x2DC0 LUT.1904
0x2DC4 LUT.1905
0x2DC8 LUT.1906
0x2DCC LUT.1907
0x2DD0 LUT.1908
0x2DD4 LUT.1909
0x2DD8 LUT.1910
0x2DDC LUT.1911
0x2DE0 LUT.1912
0x2DE4 LUT.1913
0x2DE8 LUT.1914
0x2DEC LUT.1915
0x2DF0 LUT.1916
0x2DF4 LUT.1917
0x2DF8 LUT.1918
0x2DFC LUT.1919
0x2E00 LUT.1920
0x2E04 LUT.1921
0x2E08 LUT.1922
0x2E0C LUT.1923
0x2E10 LUT.1924
0x2E14 LUT.1925
0x2E18 LUT.1926
0x2E1C LUT.1927
0x2E20 LUT.1928
0x2E24 LUT.1929
0x2E28 LUT.1930
0x2E2C LUT.1931
0x2E30 LUT.1932
0x2E34 LUT.1933
0x2E38 LUT.1934
0x2E3C LUT.1935
0x2E40 LUT.1936
0x2E44 LUT.1937
0x2E48 LUT.1938
0x2E4C LUT.1939
0x2E50 LUT.1940
0x2E54 LUT.1941
0x2E58 LUT.1942
0x2E5C LUT.1943
0x2E60 LUT.1944
0x2E64 LUT.1945
0x2E68 LUT.1946
0x2E6C LUT.1947
0x2E70 LUT.1948
0x2E74 LUT.1949
0x2E78 LUT.1950
0x2E7C LUT.1951
0x2E80 LUT.1952
0x2E84 LUT.1953
0x2E88 LUT.1954
0x2E8C LUT.1955
0x2E90 LUT.1956
0x2E94 LUT.1957
0x2E98 LUT.1958
0x2E9C LUT.1959
0x2EA0 LUT.1960
0x2EA4 LUT.1961
0x2EA8 LUT.1962
0x2EAC LUT.1963
0x2EB0 LUT.1964
0x2EB4 LUT.1965
0x2EB8 LUT.1966
0x2EBC LUT.1967
0x2EC0 LUT.1968
0x2EC4 LUT.1969
0x2EC8 LUT.1970
0x2ECC LUT.1971
0x2ED0 LUT.1972
0x2ED4 LUT.1973
0x2ED8 LUT.1974
0x2EDC LUT.1975
0x2EE0 LUT.1976
0x2EE4 LUT.1977
0x2EE8 LUT.1978
0x2EEC LUT.1979
0x2EF0 LUT.1980
0x2EF4 LUT.1981
0x2EF8 LUT.1982
0x2EFC LUT.1983
0x2F00 LUT.1984
0x2F04 LUT.1985
0x2F08 LUT.1986
0x2F0C LUT.1987
0x2F10 LUT.1988
0x2F14 LUT.1989
0x2F18 LUT.1990
0x2F1C LUT.1991
0x2F20 LUT.1992
0x2F24 LUT.1993
0x2F28 LUT.1994
0x2F2C LUT.1995
0x2F30 LUT.1996
0x2F34 LUT.1997
0x2F38 LUT.1998
0x2F3C LUT.1999
0x2F40 LUT.2000
0x2F44 LUT.2001
0x2F48 LUT.2002
0x2F4C LUT.2003
0x2F50 LUT.2004
0x2F54 LUT.2005
0x2F58 LUT.2006
0x2F5C LUT.2007
0x2F60 LUT.2008
0x2F64 LUT.2009
0x2F68 LUT.2010
0x2F6C LUT.2011
0x2F70 LUT.2012
0x2F74 LUT.2013
0x2F78 LUT.2014
0x2F7C LUT.2015
0x2F80 LUT.2016
0x2F84 LUT.2017
0x2F88 LUT.2018
0x2F8C LUT.2019
0x2F90 LUT.2020
0x2F94 LUT.2021
0x2F98 LUT.2022
0x2F9C LUT.2023
0x2FA0 LUT.2024
0x2FA4 LUT.2025
0x2FA8 LUT.2026
0x2FAC LUT.2027
0x2FB0 LUT.2028
0x2FB4 LUT.2029
0x2FB8 LUT.2030
0x2FBC LUT.2031
0x2FC0 LUT.2032
0x2FC4 LUT.2033
0x2FC8 LUT.2034
0x2FCC LUT.2035
0x2FD0 LUT.2036
0x2FD4 LUT.2037
0x2FD8 LUT.2038
0x2FDC LUT.2039
0x2FE0 LUT.2040
0x2FE4 LUT.2041
0x2FE8 LUT.2042
0x2FEC LUT.2043
0x2FF0 LUT.2044
0x2FF4 LUT.2045
0x2FF8 LUT.2046
0x2FFC LUT.2047
